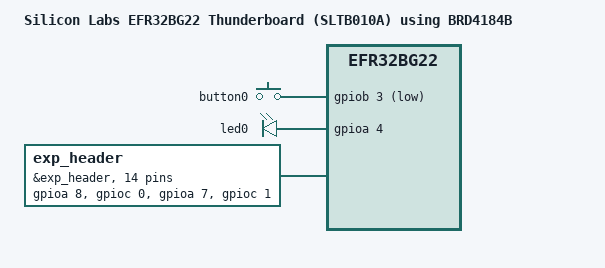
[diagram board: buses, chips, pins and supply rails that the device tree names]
/*
 * Copyright (c) 2021 Sateesh Kotapati
 * Copyright (c) 2023 Piotr Dymacz
 *
 * SPDX-License-Identifier: Apache-2.0
 */

/ {
	model = "Silicon Labs EFR32BG22 Thunderboard (SLTB010A) using BRD4184B";
	compatible = "silabs,efr32bg22c224f512im40", "silabs,sltb010a",
		     "silabs,efr32bg22";
};

&button0 {
	gpios = <&gpiob 3 GPIO_ACTIVE_LOW>;
};

&led0 {
	gpios = <&gpioa 4 GPIO_ACTIVE_HIGH>;
};

&sw_sensor_enable {
	enable-gpios = <&gpioc 6 GPIO_ACTIVE_HIGH>;
};

&sw_mic_enable {
	enable-gpios = <&gpioc 7 GPIO_ACTIVE_HIGH>;
};

&exp_header {
	gpio-map = <3 0 &gpioa 8 0>,
		   <4 0 &gpioc 0 0>,
		   <5 0 &gpioa 7 0>,
		   <6 0 &gpioc 1 0>,
		   <7 0 &gpiob 0 0>,
		   <8 0 &gpioc 2 0>,
		   <9 0 &gpiob 1 0>,
		   <10 0 &gpiob 2 0>,
		   <11 0 &gpioa 4 0>,
		   <12 0 &gpioa 5 0>,
		   <13 0 &gpiob 3 0>,
		   <14 0 &gpioa 6 0>,
		   <15 0 &gpiod 3 0>,
		   <16 0 &gpiod 2 0>;
};
